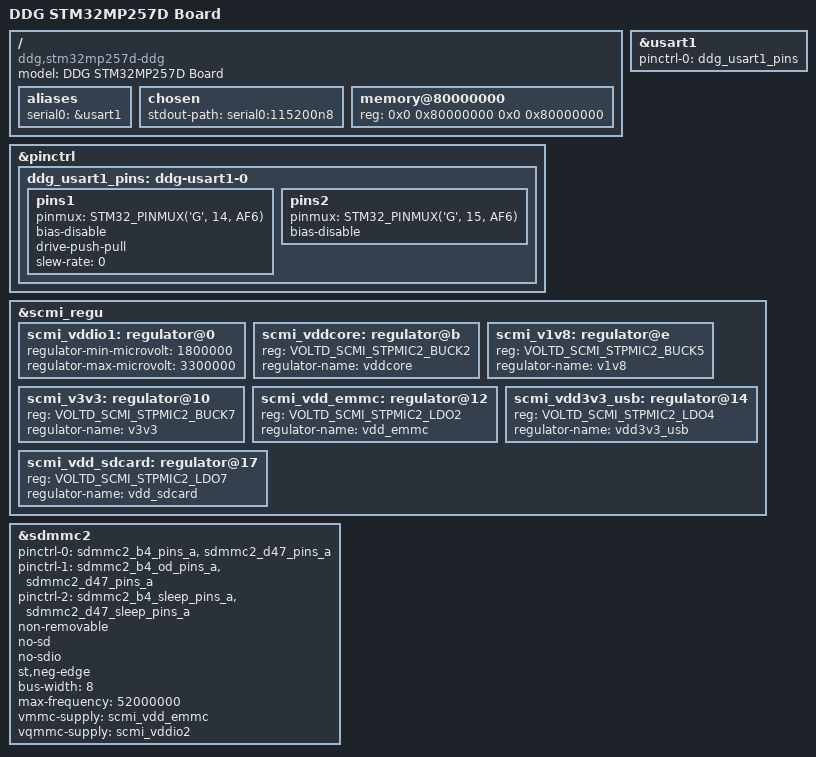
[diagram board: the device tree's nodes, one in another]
/dts-v1/;

#include <dt-bindings/pinctrl/stm32-pinfunc.h>
#include <dt-bindings/regulator/st,stm32mp25-regulator.h>

#include "stm32mp257.dtsi"
#include "stm32mp25-pinctrl.dtsi"
#include "stm32mp25xxak-pinctrl.dtsi"
#include "stm32mp257d-ddg-resmem.dtsi"

/ {
    model = "DDG STM32MP257D Board";
    compatible = "ddg,stm32mp257d-ddg", "st,stm32mp257";

    aliases {
        serial0 = &usart1;
    };

    chosen {
        stdout-path = "serial0:115200n8";
    };

    memory@80000000 {
        device_type = "memory";
        reg = <0x0 0x80000000 0x0 0x80000000>;
    };
};

&pinctrl {
    ddg_usart1_pins: ddg-usart1-0 {
        bootph-all;

        pins1 {
            bootph-all;
            pinmux = <STM32_PINMUX('G', 14, AF6)>;
            bias-disable;
            drive-push-pull;
            slew-rate = <0>;
        };

        pins2 {
            bootph-all;
            pinmux = <STM32_PINMUX('G', 15, AF6)>;
            bias-disable;
        };
    };
};

&usart1 {
    bootph-all;
    pinctrl-names = "default";
    pinctrl-0 = <&ddg_usart1_pins>;
    /delete-property/ dmas;
    /delete-property/ dma-names;
    status = "okay";
};

&scmi_regu {
	scmi_vddio1: regulator@0 {
		regulator-min-microvolt = <1800000>;
		regulator-max-microvolt = <3300000>;
	};
	scmi_vddcore: regulator@b {
		reg = <VOLTD_SCMI_STPMIC2_BUCK2>;
		regulator-name = "vddcore";
	};
	scmi_v1v8: regulator@e {
		reg = <VOLTD_SCMI_STPMIC2_BUCK5>;
		regulator-name = "v1v8";
	};
	scmi_v3v3: regulator@10 {
		reg = <VOLTD_SCMI_STPMIC2_BUCK7>;
		regulator-name = "v3v3";
	};
	scmi_vdd_emmc: regulator@12 {
		reg = <VOLTD_SCMI_STPMIC2_LDO2>;
		regulator-name = "vdd_emmc";
	};
	scmi_vdd3v3_usb: regulator@14 {
		reg = <VOLTD_SCMI_STPMIC2_LDO4>;
		regulator-name = "vdd3v3_usb";
	};
	scmi_vdd_sdcard: regulator@17 {
		reg = <VOLTD_SCMI_STPMIC2_LDO7>;
		regulator-name = "vdd_sdcard";
	};
};

&sdmmc2 {
    pinctrl-names = "default", "opendrain", "sleep";
    pinctrl-0 = <&sdmmc2_b4_pins_a &sdmmc2_d47_pins_a>;
    pinctrl-1 = <&sdmmc2_b4_od_pins_a &sdmmc2_d47_pins_a>;
    pinctrl-2 = <&sdmmc2_b4_sleep_pins_a &sdmmc2_d47_sleep_pins_a>;

    non-removable;
    no-sd;
    no-sdio;
    st,neg-edge;
    bus-width = <8>;
    max-frequency = <52000000>;

    vmmc-supply = <&scmi_vdd_emmc>;
    vqmmc-supply = <&scmi_vddio2>;

    status = "okay";
};
